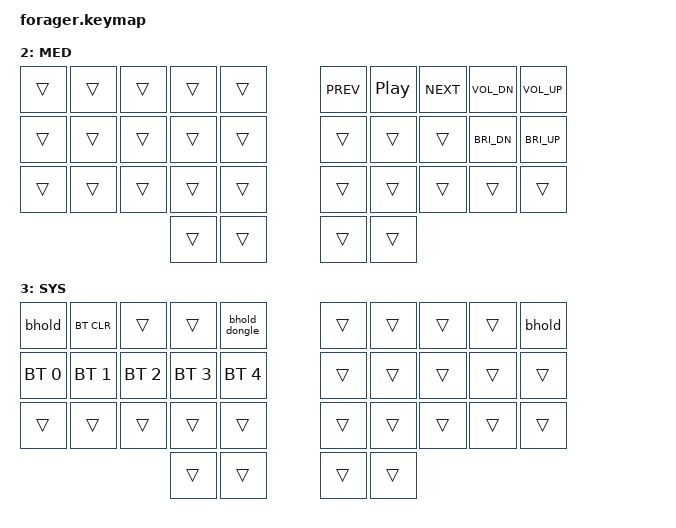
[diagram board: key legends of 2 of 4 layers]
// Copyright (c) 2022 The ZMK Contributors
// SPDX-License-Identifier: MIT

#include <behaviors.dtsi>
#include <dt-bindings/zmk/keys.h>
#include <dt-bindings/zmk/bt.h>
#include <dt-bindings/zmk/outputs.h>

// Home row mods macro
#define HRML(k1,k2,k3,k4) &hml LSHIFT k1 &hml LCTRL k2  &hml LALT k3  &hml LGUI k4
#define HRMR(k1,k2,k3,k4) &hmr RGUI k1  &hmr RALT k2  &hmr RCTRL k3  &hmr RSHIFT k4

// Key positions for positional hold-tap. Kept for reference; currently unused
// since the homerow mods below do not use cross-hand gating (see note on hml).
#define KEYS_L 0 1 2 3 4 10 11 12 13 14 20 21 22 23 24   // left-hand keys
#define KEYS_R 5 6 7 8 9 15 16 17 18 19 25 26 27 28 29   // right-hand keys
#define THUMBS 30 31 32 33                               // thumb keys

#define L0 0
#define L1 1
#define L2 2
#define L3 3

// Layer-tap, used by the right outer thumb `&lt L1 SPACE`.
//
// ZMK's stock `&lt` is `tap-preferred`, which only resolves a hold when the
// tapping term expires -- pressing and releasing another key while it is held
// does NOT trigger the hold. So a quick layer chord (hold the thumb, tap a
// key, release) completed inside 200ms emits SPACE plus that key instead of
// the layer keycode. `balanced` resolves the hold as soon as another key is
// pressed and released, which is exactly what a layer chord looks like.
//
// Thumb and homerow timings were shortened to bias toward HOLD after real use
// showed missed holds (TAP when HOLD wanted) far outnumbered false holds.
&lt {
    flavor = "balanced";
    tapping-term-ms = <175>;
    quick-tap-ms = <125>;
};

/ {
    behaviors {
        // Thumb hold-tap (drives the &ht LSHIFT TAB thumb key).
        //
        // Deliberately has NO `global-quick-tap` / `require-prior-idle-ms`.
        // Those make ZMK resolve the key to an *instant tap* whenever any other
        // key was pressed within the preceding window (150ms), no matter how
        // long or how hard the key is then held -- see is_quick_tap() in ZMK's
        // behavior_hold_tap.c. Since Shift is nearly always pressed immediately
        // after typing a letter, that reliably emitted TAB instead of SHIFT.
        //
        // Prior-idle gating is right for homerow mods (see hml/hmr below), but
        // wrong for thumbs, which are never pressed accidentally while typing.
        // Shorter than urob's 200/175 so SHIFT resolves sooner and a re-press
        // shortly after a TAB tap still becomes a hold.
        ht: hold_tap {
            label = "hold_tap";
            compatible = "zmk,behavior-hold-tap";
            #binding-cells = <2>;
            flavor = "balanced";
            tapping-term-ms = <175>;
            quick-tap-ms = <125>;
            bindings = <&kp>, <&kp>;
        };

        // Homerow mods.
        //
        // NOTE: no `hold-trigger-key-positions` / `hold-trigger-on-release`.
        // Those implement urob's cross-hand ("timeless") positional hold-tap,
        // where a homerow mod can ONLY resolve as a hold if the next key is on
        // the opposite half. That gate is absolute -- there is no timeout
        // escape hatch -- so holding LGUI (F) and pressing C, both left hand,
        // can never become a hold and just emits "fc". That breaks the whole
        // left-hand shortcut cluster (CMD/CTRL + Q W A S Z X C V) and every
        // left-hand capital via LSHIFT on A.
        //
        // With the positional gate removed, `require-prior-idle-ms` is the
        // main guard against false mods mid-word, and the tapping term becomes
        // the window in which a same-hand roll could still resolve as a hold
        // (balanced resolves on the other key's release). It was 220ms with a
        // 150ms prior-idle, which in practice dropped too many intended holds
        // (e.g. a shortcut started soon after typing). 190ms / 100ms idle
        // shifts the balance toward HOLD without going hold-preferred.
        //
        // Trade-off: a fast same-hand roll that *starts* on the homerow after
        // >100ms idle ("as", "sad", "fad") can register a mod. If that becomes
        // the more annoying failure mode, re-add the two properties below
        // (KEYS_R THUMBS for hml, KEYS_L THUMBS for hmr) and use combos for
        // same-hand shortcuts, which is how urob handles it.
        hml: home_row_mod_left {
            label = "hrm_left";
            compatible = "zmk,behavior-hold-tap";
            #binding-cells = <2>;
            flavor = "balanced";
            tapping-term-ms = <190>;
            quick-tap-ms = <120>;
            require-prior-idle-ms = <100>;
            bindings = <&kp>, <&kp>;
        };

        hmr: home_row_mod_right {
            label = "hrm_right";
            compatible = "zmk,behavior-hold-tap";
            #binding-cells = <2>;
            flavor = "balanced";
            tapping-term-ms = <190>;
            quick-tap-ms = <120>;
            require-prior-idle-ms = <100>;
            bindings = <&kp>, <&kp>;
        };
        // Caps word behavior
        caps_word: caps_word {
            compatible = "zmk,behavior-caps-word";
            #binding-cells = <0>;
        };

        bhold: bootloader_hold {
            compatible = "zmk,behavior-long-press";
            #binding-cells = <0>;
            duration-ms = <2000>;
            bindings = <&bootloader>;
        };

        // Same 2s hold, retargeted at the split central via `central`. In
        // dongle mode that is the keyless USB dongle, which otherwise can only
        // reach its UF2 bootloader by opening its case. Standalone, the central
        // is the left half, so this just duplicates the left pinky hold.
        bhold_dongle: bootloader_hold_dongle {
            compatible = "zmk,behavior-long-press";
            #binding-cells = <0>;
            duration-ms = <2000>;
            bindings = <&bootloader>;
            central;
        };
    };

    combos {
        compatible = "zmk,combos";
        // Letter combos need both keys within 25ms (ZMK's default is 50ms), so
        // quick rolls while typing, like O then P, stay as plain letters.
        combo_esc_op {
            timeout-ms = <25>;
            key-positions = <8 9>;  // Combo o+p for ESCAPE
            bindings = <&kp ESC>;
        };
        combo_esc_qw {
            timeout-ms = <25>;
            key-positions = <0 1>;  // Combo q+w for ESCAPE
            bindings = <&kp ESC>;
        };
        combo_caps_word_left {
            timeout-ms = <25>;
            key-positions = <20 21>;  // Combo Z+X for CAPS WORD (left)
            bindings = <&caps_word>;
        };
        combo_caps_word_right {
            timeout-ms = <25>;
            key-positions = <28 29>;  // Combo .+/ for CAPS WORD (right)
            bindings = <&caps_word>;
        };
        combo_maintenance_layer {
            timeout-ms = <100>;
            key-positions = <30 33>;
            bindings = <&mo L3>;
            layers = <L0 L1 L2>;
        };
    };

    keymap {
        compatible = "zmk,keymap";
        layer_zero {
            display-name = "ABC";
            bindings = <
        // ╭─────────────┬─────────────┬─────────────┬─────────────┬─────[...]
            &kp Q         &kp W         &kp E         &kp R         &kp T                   &kp Y         &kp U         &kp I         &kp O         &kp P
        // ├─────────────┼─────────────┼─────────────┼─────────────┼─────[...]
            HRML(A,           S,            D,            F)        &kp G                   &kp H         HRMR(J,           K,            L,            BSLH)
        // ├─────────────┼─────────────┼─────────────┼─────────────┼─────[...]
            &kp Z         &kp X         &kp C         &kp V         &kp B                   &kp N         &kp M          &kp COMMA    &kp DOT       &kp FSLH
        // ╰─────────────┴─────────────┴─────────────┼─────────────┼─────[...]
                                                       &kp ENTER     &ht LSHIFT TAB          &lt L1 SPACE  &kp BSPC
        //                                           ╰─────────────┴─────────────╯         ╰─────────────┴─[...]
            >;
        };


        layer_one {
            display-name = "NUM";
            bindings = <
        // ╭─────────────┬─────────────┬─────────────┬─────────────┬─────[...]
            &kp ESC       &kp N1        &kp N2        &kp N3        &trans                  &trans        &trans        &kp UARW      &kp MINUS     &kp EQUAL
        // ├─────────────┼─────────────┼─────────────┼─────────────┼─────[...]
            HRML(GRAVE,       N4,           N5,           N6)       &trans                  &trans        &kp LARW      &kp DARW      &kp RARW      &trans
        // ├─────────────┼─────────────┼─────────────┼─────────────┼─────[...]
            &trans        &kp N7        &kp N8        &kp N9        &kp N0                  &kp SEMI      &kp SQT       &kp LBKT      &kp RBKT      &trans
        // ╰─────────────┴─────────────┴─────────────┼─────────────┼─────[...]
                                                       &trans        &trans                  &trans        &trans
        //                                           ╰─────────────┴─────────────╯         ╰─────────────┴─[...]
            >;
        };


        layer_two {
            display-name = "MED";
            bindings = <
        // ╭─────────────┬─────────────┬─────────────┬─────────────┬─────────────╮         ╭─────────────┬─────────────┬─────────────┬─────────────┬─────────────╮
            &trans        &trans        &trans        &trans        &trans                  &kp C_PREV    &kp C_PP      &kp C_NEXT    &kp C_VOL_DN  &kp C_VOL_UP
        // ├─────────────┼─────────────┼─────────────┼─────────────┼─────────────┤         ├─────────────┼─────────────┼─────────────┼─────────────┼─────────────┤
            &trans        &trans        &trans        &trans        &trans                  &trans        &trans        &trans        &kp C_BRI_DN  &kp C_BRI_UP
        // ├─────────────┼─────────────┼─────────────┼─────────────┼─────────────┤         ├─────────────┼─────────────┼─────────────┼─────────────┼─────────────┤
            &trans        &trans        &trans        &trans        &trans                  &trans        &trans        &trans        &trans        &trans
        // ╰─────────────┴─────────────┴─────────────┼─────────────┼─────[...]
                                                       &trans        &trans                  &trans        &trans
        //                                           ╰─────────────┴─────────────╯         ╰─────────────┴─[...]
            >;
        };
        layer_three {
            display-name = "SYS";
            bindings = <
            &bhold        &bt BT_CLR    &trans        &trans        &bhold_dongle           &trans        &trans        &trans        &trans        &bhold
            &bt BT_SEL 0  &bt BT_SEL 1  &bt BT_SEL 2  &bt BT_SEL 3  &bt BT_SEL 4            &trans        &trans        &trans        &trans        &trans
            &trans        &trans        &trans        &trans        &trans                  &trans        &trans        &trans        &trans        &trans
                                                      &trans        &trans                  &trans        &trans
            >;
        };
    };
};
